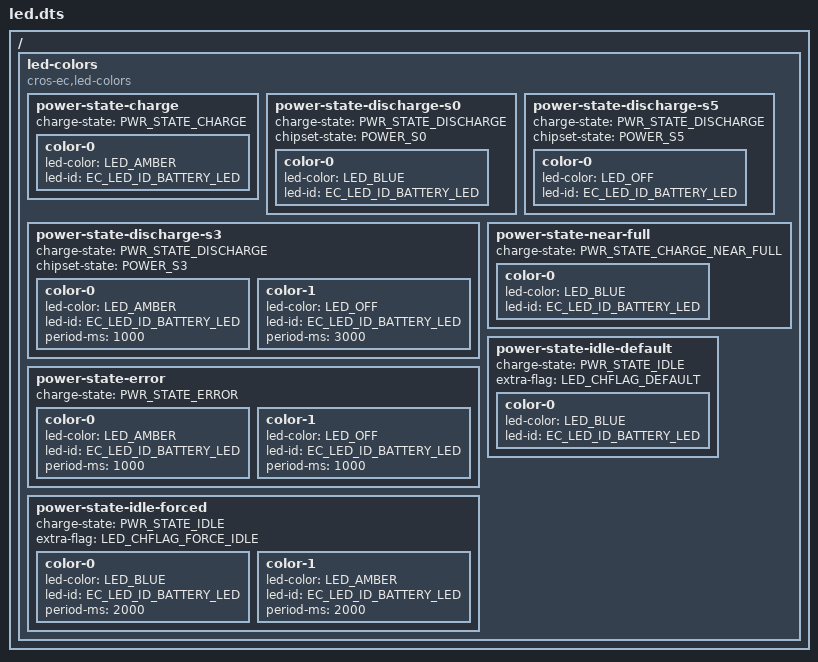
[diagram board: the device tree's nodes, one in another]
/ {
	led-colors {
		compatible = "cros-ec,led-colors";

		power-state-charge {
			charge-state = "PWR_STATE_CHARGE";

			color-0 {
				led-color = "LED_AMBER";
				led-id = "EC_LED_ID_BATTERY_LED";
			};
		};

		power-state-discharge-s0 {
			charge-state = "PWR_STATE_DISCHARGE";
			chipset-state = "POWER_S0";

			color-0 {
				led-color = "LED_BLUE";
				led-id = "EC_LED_ID_BATTERY_LED";
			};
		};

		power-state-discharge-s3 {
			charge-state = "PWR_STATE_DISCHARGE";
			chipset-state = "POWER_S3";

			/* Amber 1 sec, off 3 sec */
			color-0 {
				led-color = "LED_AMBER";
				led-id = "EC_LED_ID_BATTERY_LED";
				period-ms = <1000>;
			};
			color-1 {
				led-color = "LED_OFF";
				led-id = "EC_LED_ID_BATTERY_LED";
				period-ms = <3000>;
			};
		};

		power-state-discharge-s5 {
			charge-state = "PWR_STATE_DISCHARGE";
			chipset-state = "POWER_S5";

			color-0 {
				led-color = "LED_OFF";
				led-id = "EC_LED_ID_BATTERY_LED";
			};
		};

		power-state-error {
			charge-state = "PWR_STATE_ERROR";

			/* Amber 1 sec, off 1 sec */
			color-0 {
				led-color = "LED_AMBER";
				led-id = "EC_LED_ID_BATTERY_LED";
				period-ms = <1000>;
			};
			color-1 {
				led-color = "LED_OFF";
				led-id = "EC_LED_ID_BATTERY_LED";
				period-ms = <1000>;
			};
		};

		power-state-near-full {
			charge-state = "PWR_STATE_CHARGE_NEAR_FULL";

			color-0 {
				led-color = "LED_BLUE";
				led-id = "EC_LED_ID_BATTERY_LED";
			};
		};

		power-state-idle-forced {
			charge-state = "PWR_STATE_IDLE";
			extra-flag = "LED_CHFLAG_FORCE_IDLE";

			/* Blue 2 sec, Amber 2 sec */
			color-0 {
				led-color = "LED_BLUE";
				led-id = "EC_LED_ID_BATTERY_LED";
				period-ms = <2000>;
			};
			color-1 {
				led-color = "LED_AMBER";
				led-id = "EC_LED_ID_BATTERY_LED";
				period-ms = <2000>;
			};
		};

		power-state-idle-default {
			charge-state = "PWR_STATE_IDLE";
			extra-flag = "LED_CHFLAG_DEFAULT";

			color-0 {
				led-color = "LED_BLUE";
				led-id = "EC_LED_ID_BATTERY_LED";
			};
		};
	};
};
